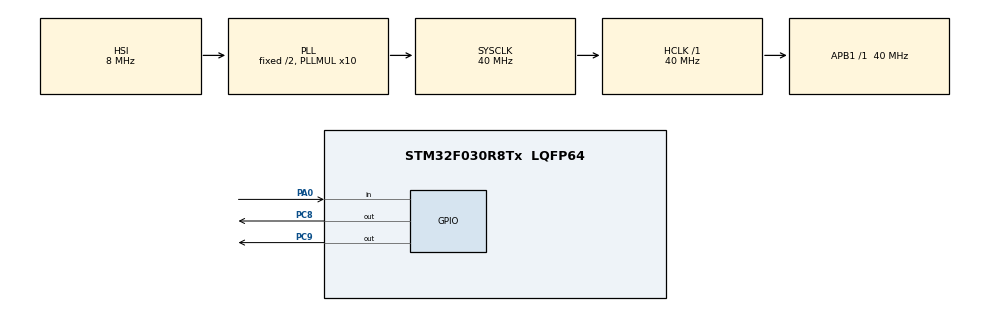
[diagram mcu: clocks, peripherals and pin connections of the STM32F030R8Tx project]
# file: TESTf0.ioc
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Mcu.Family=STM32F0
Mcu.Name=STM32F030R8Tx
Mcu.Package=LQFP64
PA0.GPIO_PuPd=GPIO_PULLDOWN
PA0.Signal=GPIO_Input
PC8.GPIO_Speed=GPIO_SPEED_FREQ_HIGH
PC8.PinState=GPIO_PIN_SET
PC8.Signal=GPIO_Output
PC9.GPIO_Speed=GPIO_SPEED_FREQ_HIGH
PC9.PinState=GPIO_PIN_SET
PC9.Signal=GPIO_Output
ProjectManager.HeapSize=0x200
ProjectManager.StackSize=0x400
ProjectManager.TargetToolchain=MDK-ARM V5
RCC.AHBFreq_Value=40000000
RCC.APB1Freq_Value=40000000
RCC.APB1TimFreq_Value=40000000
RCC.HCLKFreq_Value=40000000
RCC.PLLMUL=RCC_PLL_MUL10
RCC.SYSCLKFreq_VALUE=40000000
RCC.SYSCLKSource=RCC_SYSCLKSOURCE_PLLCLK
board=custom

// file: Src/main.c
/* USER CODE BEGIN Header */
/**
  ******************************************************************************
  * @file           : main.c
  * @brief          : Main program body
  ******************************************************************************
  ** This notice applies to any and all portions of this file
  * that are not between comment pairs USER CODE BEGIN and
  * USER CODE END. Other portions of this file, whether
  * inserted by the user or by software development tools
  * are owned by their respective copyright owners.
  *
  * COPYRIGHT(c) 2019 STMicroelectronics
  *
  * Redistribution and use in source and binary forms, with or without modification,
  * are permitted provided that the following conditions are met:
  *   1. Redistributions of source code must retain the above copyright notice,
  *      this list of conditions and the following disclaimer.
  *   2. Redistributions in binary form must reproduce the above copyright notice,
  *      this list of conditions and the following disclaimer in the documentation
  *      and/or other materials provided with the distribution.
  *   3. Neither the name of STMicroelectronics nor the names of its contributors
  *      may be used to endorse or promote products derived from this software
  *      without specific prior written permission.
  *
  * THIS SOFTWARE IS PROVIDED BY THE COPYRIGHT HOLDERS AND CONTRIBUTORS "AS IS"
  * AND ANY EXPRESS OR IMPLIED WARRANTIES, INCLUDING, BUT NOT LIMITED TO, THE
  * IMPLIED WARRANTIES OF MERCHANTABILITY AND FITNESS FOR A PARTICULAR PURPOSE ARE
  * DISCLAIMED. IN NO EVENT SHALL THE COPYRIGHT HOLDER OR CONTRIBUTORS BE LIABLE
  * FOR ANY DIRECT, INDIRECT, INCIDENTAL, SPECIAL, EXEMPLARY, OR CONSEQUENTIAL
  * DAMAGES (INCLUDING, BUT NOT LIMITED TO, PROCUREMENT OF SUBSTITUTE GOODS OR
  * SERVICES; LOSS OF USE, DATA, OR PROFITS; OR BUSINESS INTERRUPTION) HOWEVER
  * CAUSED AND ON ANY THEORY OF LIABILITY, WHETHER IN CONTRACT, STRICT LIABILITY,
  * OR TORT (INCLUDING NEGLIGENCE OR OTHERWISE) ARISING IN ANY WAY OUT OF THE USE
  * OF THIS SOFTWARE, EVEN IF ADVISED OF THE POSSIBILITY OF SUCH DAMAGE.
  *
  ******************************************************************************
  */
/* USER CODE END Header */

#include "main.h"

/* USER CODE BEGIN PV */
#define TASK_NUM (2)
unsigned int TaskCount[TASK_NUM];
unsigned char TaskMark[TASK_NUM];
typedef struct _TASK_COMPONENTS
{
    unsigned char Run;
    unsigned int Timer;
    unsigned int ItvTime;
    void (*TaskHook)(void);
} TASK_COMPONENTS;

/* USER CODE END PV */

void SystemClock_Config(void);
static void MX_GPIO_Init(void);
/* USER CODE BEGIN PFP */
void TimerInterrupt(void);
void TaskRemarks(void);
void TaskProcess(void);
void LEDTask1(void);
void LEDTask2(void);
void InputIOScan(void);
/* USER CODE END PFP */

/* USER CODE BEGIN 0 */
int testcount = 0;
uint32_t sysclock = 0;
uint32_t SysClockFreq = 0;
//static unsigned char LEDFlag = 0;
//static unsigned int Leddisptimer = 0;

static TASK_COMPONENTS TaskComps[] =
{
    {0, 500, 500, LEDTask1},
    {0, 1000, 1000, LEDTask2},
};

enum {
    KEY_INVALID=0,
    KEY_PRESS_VALID,
    KEY_LONGPRESS_VALID,
    KEY_RELEASE,
    KEY_LONGPRESS_RELEASE
};
typedef unsigned char KEY_DEAL_STATE;

/* USER CODE END 0 */

int main(void)
{
  /* USER CODE BEGIN 1 */
	TaskCount[0] = 500;
  TaskCount[1] = 1000;
  TaskMark[0]  = 0x00;
	TaskMark[1]  = 0x00;
  /* USER CODE END 1 */

  /* MCU Configuration--------------------------------------------------------*/

  /* Reset of all peripherals, Initializes the Flash interface and the Systick. */
  HAL_Init();

  /* Configure the system clock */
  SystemClock_Config();

  /* Initialize all configured peripherals */
  MX_GPIO_Init();
  /* USER CODE BEGIN 2 */
  sysclock = HAL_RCC_GetSysClockFreq();
	SysClockFreq = HAL_RCC_GetHCLKFreq();
  /* USER CODE END 2 */

  /* Infinite loop */
  /* USER CODE BEGIN WHILE */
  while (1)
  {
		testcount++;
		//=================================================================1
		/*
//		if(0 == g_uiSystick%1000)
		if ((g_uiSystick-Leddisptimer)>1000)
		{
			switch(LEDFlag)
			{
				case 0:
					LEDFlag = 1;
				  HAL_GPIO_WritePin(GPIOC, GPIO_PIN_8|GPIO_PIN_9, GPIO_PIN_SET);
					break;
				case 1:
					LEDFlag = 0;
				  HAL_GPIO_WritePin(GPIOC, GPIO_PIN_8|GPIO_PIN_9, GPIO_PIN_RESET);
					break;
				default:
					break;
			}
			Leddisptimer = g_uiSystick;
		}*/
		//==================================================================2
		/*
		if(1 == TaskMark[0])
		{
			LEDTask1();
      TaskMark[0] = 0;
			TaskCount[0] = 500;
		}
		if(1 == TaskMark[1])
		{
			LEDTask2();
			TaskMark[1] = 0;
			TaskCount[1] = 1000;
		}*/
		//==================================================================3
		TaskProcess();

/*  key scan
		if(HAL_GPIO_ReadPin(GPIOA, GPIO_PIN_0))
		{
			HAL_GPIO_WritePin(GPIOC, GPIO_PIN_8, GPIO_PIN_SET);
		}
		else
		{
			HAL_GPIO_WritePin(GPIOC, GPIO_PIN_8, GPIO_PIN_RESET);
		}
*/
    InputIOScan();
    /* USER CODE END WHILE */

  }
}

void SystemClock_Config(void)
{
  RCC_OscInitTypeDef RCC_OscInitStruct = {0};
  RCC_ClkInitTypeDef RCC_ClkInitStruct = {0};

  /**Initializes the CPU, AHB and APB busses clocks
  */
  RCC_OscInitStruct.OscillatorType = RCC_OSCILLATORTYPE_HSI;
  RCC_OscInitStruct.HSIState = RCC_HSI_ON;
  RCC_OscInitStruct.HSICalibrationValue = RCC_HSICALIBRATION_DEFAULT;
  RCC_OscInitStruct.PLL.PLLState = RCC_PLL_ON;
  RCC_OscInitStruct.PLL.PLLSource = RCC_PLLSOURCE_HSI;
  RCC_OscInitStruct.PLL.PLLMUL = RCC_PLL_MUL10;
  RCC_OscInitStruct.PLL.PREDIV = RCC_PREDIV_DIV1;
  if (HAL_RCC_OscConfig(&RCC_OscInitStruct) != HAL_OK)
  {
    Error_Handler();
  }
  /**Initializes the CPU, AHB and APB busses clocks
  */
  RCC_ClkInitStruct.ClockType = RCC_CLOCKTYPE_HCLK|RCC_CLOCKTYPE_SYSCLK
                              |RCC_CLOCKTYPE_PCLK1;
  RCC_ClkInitStruct.SYSCLKSource = RCC_SYSCLKSOURCE_PLLCLK;
  RCC_ClkInitStruct.AHBCLKDivider = RCC_SYSCLK_DIV1;
  RCC_ClkInitStruct.APB1CLKDivider = RCC_HCLK_DIV1;

  if (HAL_RCC_ClockConfig(&RCC_ClkInitStruct, FLASH_LATENCY_1) != HAL_OK)
  {
    Error_Handler();
  }
}

static void MX_GPIO_Init(void)
{
  GPIO_InitTypeDef GPIO_InitStruct = {0};

  /* GPIO Ports Clock Enable */
  __HAL_RCC_GPIOA_CLK_ENABLE();
  __HAL_RCC_GPIOC_CLK_ENABLE();

  /*Configure GPIO pin Output Level */
  HAL_GPIO_WritePin(GPIOC, GPIO_PIN_8|GPIO_PIN_9, GPIO_PIN_SET);

  /*Configure GPIO pin : PA0 */
  GPIO_InitStruct.Pin = GPIO_PIN_0;
  GPIO_InitStruct.Mode = GPIO_MODE_INPUT;
  GPIO_InitStruct.Pull = GPIO_PULLDOWN;
  HAL_GPIO_Init(GPIOA, &GPIO_InitStruct);

  /*Configure GPIO pins : PC8 PC9 */
  GPIO_InitStruct.Pin = GPIO_PIN_8|GPIO_PIN_9;
  GPIO_InitStruct.Mode = GPIO_MODE_OUTPUT_PP;
  GPIO_InitStruct.Pull = GPIO_NOPULL;
  GPIO_InitStruct.Speed = GPIO_SPEED_FREQ_HIGH;
  HAL_GPIO_Init(GPIOC, &GPIO_InitStruct);

}

/* USER CODE BEGIN 4 */
void TimerInterrupt(void)
{
    unsigned char i;
    for (i=0; i<TASK_NUM; i++)
    {
        if (TaskCount[i])
        {
              TaskCount[i]--;
              if (TaskCount[i] == 0)
              {
                    TaskMark[i] = 0x01;
              }
        }
   }
}

void TaskRemarks(void)
{
    unsigned char i;

    for (i=0; i<TASK_NUM; i++)
    {
         if (TaskComps[i].Timer)
        {
            TaskComps[i].Timer--;
            if (TaskComps[i].Timer == 0)
            {
                 TaskComps[i].Timer = TaskComps[i].ItvTime;
                 TaskComps[i].Run = 1;
            }
        }
   }
}

void TaskProcess(void)
{
    unsigned char i;

    for (i=0; i<TASK_NUM; i++)
    {
        if (TaskComps[i].Run)
        {
             TaskComps[i].TaskHook();
             TaskComps[i].Run = 0;
        }
    }
}

void LEDTask1(void)
{
	static unsigned char flag1 = 0;
	switch(flag1)
	{
		case 0:
			flag1 = 1;
//			HAL_GPIO_WritePin(GPIOC, GPIO_PIN_8, GPIO_PIN_SET);
			break;
		case 1:
			flag1 = 0;
//			HAL_GPIO_WritePin(GPIOC, GPIO_PIN_8, GPIO_PIN_RESET);
			break;
		default:
			break;
	}
}

void LEDTask2(void)
{
	static unsigned char flag2 = 0;
	switch(flag2)
	{
		case 0:
			flag2 = 1;
			HAL_GPIO_WritePin(GPIOC, GPIO_PIN_9, GPIO_PIN_SET);
			break;
		case 1:
			flag2 = 0;
			HAL_GPIO_WritePin(GPIOC, GPIO_PIN_9, GPIO_PIN_RESET);
			break;
		default:
			break;
	}
}

KEY_DEAL_STATE InputSCanStateM_Ex(unsigned char *pstate, unsigned char *poldvalue, unsigned char curvalue,unsigned int *pTimer,unsigned int maxdelay,unsigned int validtime)
{
  KEY_DEAL_STATE ret = KEY_INVALID;
  unsigned char oldvalue = *poldvalue;
  switch(*pstate)
  {
  case 0:
    if(curvalue != oldvalue)
    {
      (*pstate)++;
      (*pTimer) = g_uiSystick;
    }
    break;
  case 1:
    if(curvalue!=oldvalue)
    {
      if(((g_uiSystick-(*pTimer))>maxdelay))
      {
        ret = KEY_PRESS_VALID;
        (*pstate)++;
        (*pTimer) = g_uiSystick;
      }
    }
    else
    {
      (*pstate) = 0;
    }
    break;
  case 2:
    if(curvalue!=oldvalue)
    {
      if(g_uiSystick-(*pTimer)>validtime)
      {
        *poldvalue = curvalue;
        ret = KEY_LONGPRESS_VALID;
        (*pstate)++;
      }
    }
    else
    {
      (*pstate)=0;
      ret =KEY_RELEASE;
    }
    break;
  case 3:
    if(curvalue!=oldvalue)
    {
      *poldvalue=curvalue;
      (*pstate)=0;
      ret =KEY_LONGPRESS_RELEASE;
    }
    break;
  default:
    (*pstate)=0;
    break;
  }

  return ret;
}

static unsigned char state_keyinc = 0;
static unsigned char keyinc = 0;
static unsigned int timer_keyinc = 0;
void InputIOScan(void)
{
  unsigned short temp = 0;
  unsigned char ret = 0;

  temp = HAL_GPIO_ReadPin(GPIOA, GPIO_PIN_0);
  ret = InputSCanStateM_Ex(&state_keyinc, &keyinc, temp, &timer_keyinc, 20, 2000);//按键消抖20ms，长按时间设为2000ms
  switch(ret)
  {
  case KEY_INVALID:
    break;

  case KEY_PRESS_VALID:

    break;

  case KEY_LONGPRESS_VALID:
		HAL_GPIO_WritePin(GPIOC, GPIO_PIN_8, GPIO_PIN_SET);
    break;

  case KEY_RELEASE:
		HAL_GPIO_WritePin(GPIOC, GPIO_PIN_8, GPIO_PIN_RESET);
  case KEY_LONGPRESS_RELEASE:
		HAL_GPIO_WritePin(GPIOC, GPIO_PIN_8, GPIO_PIN_RESET);
    break;

  default:
    break;
  }
}
/* USER CODE END 4 */

void Error_Handler(void)
{
}

/************************ (C) COPYRIGHT STMicroelectronics *****END OF FILE****/
